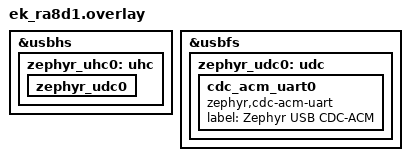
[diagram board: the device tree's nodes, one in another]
/*
 * Copyright (c) 2024 Renesas Electronics Corporation
 *
 * SPDX-License-Identifier: Apache-2.0
 */

/delete-node/ &zephyr_udc0;

&usbhs {
	status = "okay";

	zephyr_uhc0: uhc {
		status = "okay";
		zephyr_udc0 {};
	};
};

&usbfs {
	status = "okay";

	zephyr_udc0: udc {
		status = "okay";

		cdc_acm_uart0 {
			compatible = "zephyr,cdc-acm-uart";
			label = "Zephyr USB CDC-ACM";
		};
	};
};
